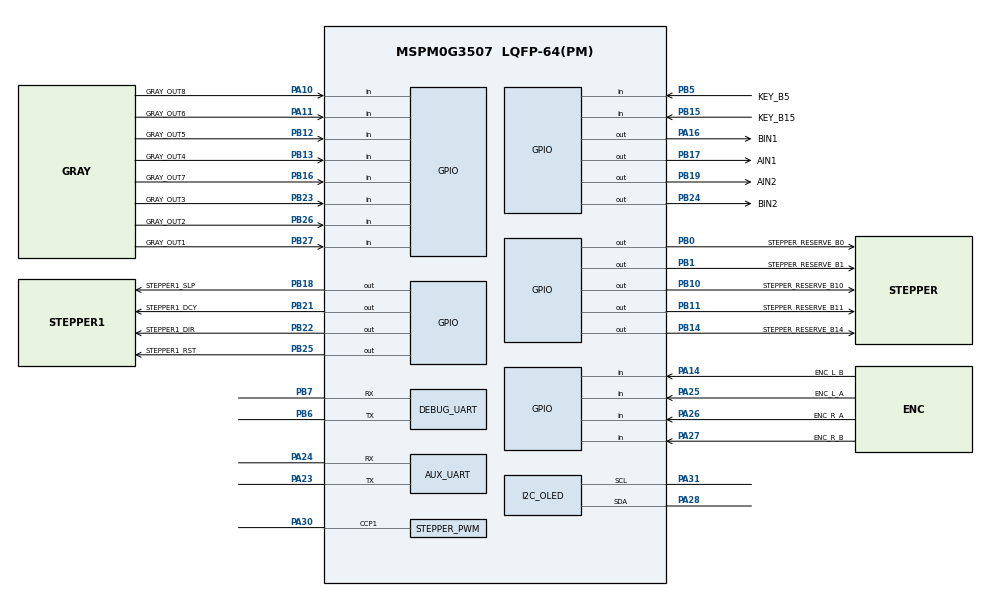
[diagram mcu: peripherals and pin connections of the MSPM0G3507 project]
/**
 * PID speed-loop test for the two-wheel car.
 *
 * Pin source: E:\EmbeddedDevelopment\二驱小车new.xlsx
 * Mapping required by the user: rear-drive car, TB6612 A channel = right rear,
 * TB6612 B channel = left rear.
 */
//@cliArgs --device "MSPM0G350X" --package "LQFP-64(PM)" --part "Default"
//@v2CliArgs --device "MSPM0G3507" --package "LQFP-64(PM)"
// @cliArgs --board /ti/boards/LP_MSPM0G3507 --rtos nortos

const Board  = scripting.addModule("/ti/driverlib/Board", {}, false);
const GPIO   = scripting.addModule("/ti/driverlib/GPIO", {}, false);
const I2C    = scripting.addModule("/ti/driverlib/I2C", {}, false);
const PWM    = scripting.addModule("/ti/driverlib/PWM", {}, false);
const SYSCTL = scripting.addModule("/ti/driverlib/SYSCTL");
const TIMER  = scripting.addModule("/ti/driverlib/TIMER", {}, false);
const UART   = scripting.addModule("/ti/driverlib/UART", {}, false);

const GPIO_DIR     = GPIO.addInstance();
const GPIO_INPUTS  = GPIO.addInstance();
const GPIO_STEPPER = GPIO.addInstance();
const I2C_OLED     = I2C.addInstance();
const STEPPER_PWM  = PWM.addInstance();
const RUN_TIMER    = TIMER.addInstance();
const DEBUG_UART   = UART.addInstance();
const AUX_UART     = UART.addInstance();

Board.peripheral.$assign = "DEBUGSS";

SYSCTL.forceDefaultClkConfig = true;
SYSCTL.clockTreeEn = true;

GPIO_DIR.$name = "GPIO_MOTOR_DIR";
GPIO_DIR.associatedPins.create(4);
GPIO_DIR.associatedPins[0].$name = "AIN1";
GPIO_DIR.associatedPins[0].initialValue = "CLEARED";
GPIO_DIR.associatedPins[0].pin.$assign = "PB17";
GPIO_DIR.associatedPins[1].$name = "AIN2";
GPIO_DIR.associatedPins[1].initialValue = "CLEARED";
GPIO_DIR.associatedPins[1].pin.$assign = "PB19";
GPIO_DIR.associatedPins[2].$name = "BIN1";
GPIO_DIR.associatedPins[2].initialValue = "CLEARED";
GPIO_DIR.associatedPins[2].pin.$assign = "PA16";
GPIO_DIR.associatedPins[3].$name = "BIN2";
GPIO_DIR.associatedPins[3].initialValue = "CLEARED";
GPIO_DIR.associatedPins[3].pin.$assign = "PB24";

GPIO_STEPPER.$name = "GPIO_STEPPER_CTRL";
GPIO_STEPPER.associatedPins.create(9);
GPIO_STEPPER.associatedPins[0].$name = "STEPPER1_RST";
GPIO_STEPPER.associatedPins[0].initialValue = "SET";
GPIO_STEPPER.associatedPins[0].pin.$assign = "PB25";
GPIO_STEPPER.associatedPins[1].$name = "STEPPER1_SLP";
GPIO_STEPPER.associatedPins[1].initialValue = "SET";
GPIO_STEPPER.associatedPins[1].pin.$assign = "PB18";
GPIO_STEPPER.associatedPins[2].$name = "STEPPER1_DCY";
GPIO_STEPPER.associatedPins[2].initialValue = "CLEARED";
GPIO_STEPPER.associatedPins[2].pin.$assign = "PB21";
GPIO_STEPPER.associatedPins[3].$name = "STEPPER1_DIR";
GPIO_STEPPER.associatedPins[3].initialValue = "CLEARED";
GPIO_STEPPER.associatedPins[3].pin.$assign = "PB22";
GPIO_STEPPER.associatedPins[4].$name = "STEPPER_RESERVE_B0";
GPIO_STEPPER.associatedPins[4].initialValue = "CLEARED";
GPIO_STEPPER.associatedPins[4].pin.$assign = "PB0";
GPIO_STEPPER.associatedPins[5].$name = "STEPPER_RESERVE_B1";
GPIO_STEPPER.associatedPins[5].initialValue = "CLEARED";
GPIO_STEPPER.associatedPins[5].pin.$assign = "PB1";
GPIO_STEPPER.associatedPins[6].$name = "STEPPER_RESERVE_B10";
GPIO_STEPPER.associatedPins[6].initialValue = "CLEARED";
GPIO_STEPPER.associatedPins[6].pin.$assign = "PB10";
GPIO_STEPPER.associatedPins[7].$name = "STEPPER_RESERVE_B11";
GPIO_STEPPER.associatedPins[7].initialValue = "CLEARED";
GPIO_STEPPER.associatedPins[7].pin.$assign = "PB11";
GPIO_STEPPER.associatedPins[8].$name = "STEPPER_RESERVE_B14";
GPIO_STEPPER.associatedPins[8].initialValue = "CLEARED";
GPIO_STEPPER.associatedPins[8].pin.$assign = "PB14";

GPIO_INPUTS.$name = "GPIO_CAR_INPUTS";
GPIO_INPUTS.associatedPins.create(14);
GPIO_INPUTS.associatedPins[0].$name = "KEY_B5";
GPIO_INPUTS.associatedPins[0].direction = "INPUT";
GPIO_INPUTS.associatedPins[0].internalResistor = "PULL_UP";
GPIO_INPUTS.associatedPins[0].pin.$assign = "PB5";
GPIO_INPUTS.associatedPins[1].$name = "KEY_B15";
GPIO_INPUTS.associatedPins[1].direction = "INPUT";
GPIO_INPUTS.associatedPins[1].internalResistor = "PULL_UP";
GPIO_INPUTS.associatedPins[1].pin.$assign = "PB15";
GPIO_INPUTS.associatedPins[2].$name = "GRAY_OUT1";
GPIO_INPUTS.associatedPins[2].direction = "INPUT";
GPIO_INPUTS.associatedPins[2].internalResistor = "PULL_UP";
GPIO_INPUTS.associatedPins[2].pin.$assign = "PB27";
GPIO_INPUTS.associatedPins[3].$name = "GRAY_OUT2";
GPIO_INPUTS.associatedPins[3].direction = "INPUT";
GPIO_INPUTS.associatedPins[3].internalResistor = "PULL_UP";
GPIO_INPUTS.associatedPins[3].pin.$assign = "PB26";
GPIO_INPUTS.associatedPins[4].$name = "GRAY_OUT3";
GPIO_INPUTS.associatedPins[4].direction = "INPUT";
GPIO_INPUTS.associatedPins[4].internalResistor = "PULL_UP";
GPIO_INPUTS.associatedPins[4].pin.$assign = "PB23";
GPIO_INPUTS.associatedPins[5].$name = "GRAY_OUT4";
GPIO_INPUTS.associatedPins[5].direction = "INPUT";
GPIO_INPUTS.associatedPins[5].internalResistor = "PULL_UP";
GPIO_INPUTS.associatedPins[5].pin.$assign = "PB13";
GPIO_INPUTS.associatedPins[6].$name = "GRAY_OUT5";
GPIO_INPUTS.associatedPins[6].direction = "INPUT";
GPIO_INPUTS.associatedPins[6].internalResistor = "PULL_UP";
GPIO_INPUTS.associatedPins[6].pin.$assign = "PB12";
GPIO_INPUTS.associatedPins[7].$name = "GRAY_OUT6";
GPIO_INPUTS.associatedPins[7].direction = "INPUT";
GPIO_INPUTS.associatedPins[7].internalResistor = "PULL_UP";
GPIO_INPUTS.associatedPins[7].pin.$assign = "PA11";
GPIO_INPUTS.associatedPins[8].$name = "GRAY_OUT7";
GPIO_INPUTS.associatedPins[8].direction = "INPUT";
GPIO_INPUTS.associatedPins[8].internalResistor = "PULL_UP";
GPIO_INPUTS.associatedPins[8].pin.$assign = "PB16";
GPIO_INPUTS.associatedPins[9].$name = "GRAY_OUT8";
GPIO_INPUTS.associatedPins[9].direction = "INPUT";
GPIO_INPUTS.associatedPins[9].internalResistor = "PULL_UP";
GPIO_INPUTS.associatedPins[9].pin.$assign = "PA10";
GPIO_INPUTS.associatedPins[10].$name = "ENC_R_A";
GPIO_INPUTS.associatedPins[10].direction = "INPUT";
GPIO_INPUTS.associatedPins[10].internalResistor = "PULL_UP";
GPIO_INPUTS.associatedPins[10].interruptEn = true;
GPIO_INPUTS.associatedPins[10].polarity = "RISE_FALL";
GPIO_INPUTS.associatedPins[10].pin.$assign = "PA26";
GPIO_INPUTS.associatedPins[11].$name = "ENC_R_B";
GPIO_INPUTS.associatedPins[11].direction = "INPUT";
GPIO_INPUTS.associatedPins[11].internalResistor = "PULL_UP";
GPIO_INPUTS.associatedPins[11].interruptEn = true;
GPIO_INPUTS.associatedPins[11].polarity = "RISE_FALL";
GPIO_INPUTS.associatedPins[11].pin.$assign = "PA27";
GPIO_INPUTS.associatedPins[12].$name = "ENC_L_A";
GPIO_INPUTS.associatedPins[12].direction = "INPUT";
GPIO_INPUTS.associatedPins[12].internalResistor = "PULL_UP";
GPIO_INPUTS.associatedPins[12].interruptEn = true;
GPIO_INPUTS.associatedPins[12].polarity = "RISE_FALL";
GPIO_INPUTS.associatedPins[12].pin.$assign = "PA25";
GPIO_INPUTS.associatedPins[13].$name = "ENC_L_B";
GPIO_INPUTS.associatedPins[13].direction = "INPUT";
GPIO_INPUTS.associatedPins[13].internalResistor = "PULL_UP";
GPIO_INPUTS.associatedPins[13].interruptEn = true;
GPIO_INPUTS.associatedPins[13].polarity = "RISE_FALL";
GPIO_INPUTS.associatedPins[13].pin.$assign = "PA14";

STEPPER_PWM.$name = "STEPPER_PWM";
STEPPER_PWM.timerCount = 1600;
STEPPER_PWM.dutyArgs = "[0,50,0,0]";
STEPPER_PWM.enableShadowLoad = false;
STEPPER_PWM.timerStartTimer = false;
STEPPER_PWM.peripheral.$assign = "TIMG6";
STEPPER_PWM.peripheral.ccp1Pin.$assign = "PA30";
STEPPER_PWM.PWM_CHANNEL_0.$name = "STEPPER_UNUSED_C0";
STEPPER_PWM.PWM_CHANNEL_1.$name = "STEPPER_STEP_PA30";

RUN_TIMER.$name = "RUN_TIMER";
RUN_TIMER.timerMode = "PERIODIC";
RUN_TIMER.timerPeriod = "1 ms";
RUN_TIMER.timerStartTimer = true;
RUN_TIMER.interrupts = ["ZERO"];
RUN_TIMER.peripheral.$assign = "TIMG12";

DEBUG_UART.$name = "UART_0";
DEBUG_UART.profile = "CONFIG_PROFILE_1";
DEBUG_UART.peripheral.$assign = "UART1";
DEBUG_UART.targetBaudRate = 9600;
DEBUG_UART.enableInternalLoopback = false;
DEBUG_UART.enableFIFO = false;
DEBUG_UART.enabledInterrupts = ["RX"];
DEBUG_UART.peripheral.txPin.$assign = "PB6";
DEBUG_UART.peripheral.rxPin.$assign = "PB7";

AUX_UART.$name = "UART_2";
AUX_UART.profile = "CONFIG_PROFILE_1";
AUX_UART.peripheral.$assign = "UART2";
AUX_UART.targetBaudRate = 115200;
AUX_UART.enableInternalLoopback = false;
AUX_UART.enableFIFO = false;
AUX_UART.enabledInterrupts = ["RX"];
AUX_UART.peripheral.txPin.$assign = "PA23";
AUX_UART.peripheral.rxPin.$assign = "PA24";

I2C_OLED.$name = "I2C_OLED";
I2C_OLED.basicEnableController = true;
I2C_OLED.basicControllerBusSpeed = 100000;
I2C_OLED.advAnalogGlitchFilter = "DISABLED";
I2C_OLED.advControllerTXFIFOTRIG = "BYTES_1";
I2C_OLED.peripheral.$assign = "I2C0";
I2C_OLED.peripheral.sdaPin.$assign = "PA28";
I2C_OLED.peripheral.sclPin.$assign = "PA31";
I2C_OLED.sdaPinConfig.enableConfig = true;
I2C_OLED.sclPinConfig.enableConfig = true;
